# C7X256V_CORE0_C7X256V_CORE0_30240000h register map
Vendor: Texas Instruments
Peripheral module from a debugger description file (folder AM275x).
Registers are 32-bit, read-only, reset values left out (the file's numbers can be read two ways) unless marked. A register's access mark holds for its fields unless they carry their own. Offsets are as the file gives them; lines under a group give offsets from that group; [hi:lo] are bit positions; {n}, {i} and the like mark numbered series; 'fields as' and 'values as' point back to an identical list; <NAME> marks a mode.

## C7X256V_CORE0
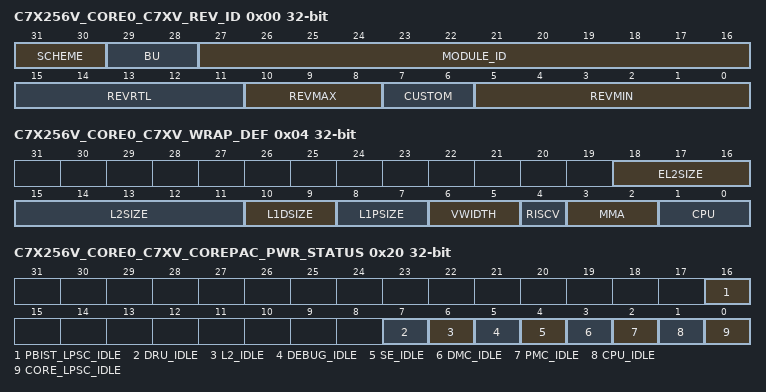
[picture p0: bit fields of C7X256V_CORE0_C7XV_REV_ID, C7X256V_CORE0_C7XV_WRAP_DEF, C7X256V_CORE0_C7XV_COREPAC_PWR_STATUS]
0x00 C7X256V_CORE0_C7XV_REV_ID — Revision parameters
  [31:30] SCHEME — Scheme Reset Source: mod_g_rst_n
  [29:28] BU — Scheme Reset Source: mod_g_rst_n
  [27:16] MODULE_ID — Module ID Reset Source: mod_g_rst_n
  [15:11] REVRTL — RTL version Reset Source: mod_g_rst_n
  [10:8] REVMAX — Major version Reset Source: mod_g_rst_n
  [7:6] CUSTOM — Custom version Reset Source: mod_g_rst_n
  [5:0] REVMIN — Minor version Reset Source: mod_g_rst_n
0x04 C7X256V_CORE0_C7XV_WRAP_DEF — Definition parameters
  [18:16] EL2SIZE — EL2 size Reset Source: mod_g_rst_n
  [15:11] L2SIZE — L2 size Reset Source: mod_g_rst_n
  [10:9] L1DSIZE — L1D size Reset Source: mod_g_rst_n
  [8:7] L1PSIZE — L1P size Reset Source: mod_g_rst_n
  [6:5] VWIDTH — Vector width size Reset Source: mod_g_rst_n
  [4] RISCV — RISCV ISA supported Reset Source: mod_g_rst_n
  [3:2] MMA — MMA type Reset Source: mod_g_rst_n
  [1:0] CPU — CPU type Reset Source: mod_g_rst_n
0x10 C7X256V_CORE0_C7XV_RESET_BOOT_VEC_L — C7xV wrap reset boot vector Register LSBs
  [31:0] RESET_BASE_VECTOR_LO — RVBARADDR0[31:0] Reset Source: mod_g_rst_n
0x14 C7X256V_CORE0_C7XV_RESET_BOOT_VEC_H — C7xV wrap reset boot vector Register MSBs
  [31:0] RESET_BASE_VECTOR_HI — RVBARADDR0[48:32] Reset Source: mod_g_rst_n
0x18 C7X256V_CORE0_C7XV_COREPAC_CFG — C7xV wrap corepac configuration register
  [0] CPU_SYS_RISCV_MODE — Enables CPU booting in RISC-V mode, default is C7xVISA mode Reset Source: mod_g_rst_n
0x1C C7X256V_CORE0_C7XV_COREPAC_PWR_CFG access not given — Configuration register
0x20 C7X256V_CORE0_C7XV_COREPAC_PWR_STATUS — C7xV wrap corepac power status register
  [16] PBIST_LPSC_IDLE — PBIST LPSC idle status Reset Source: mod_g_rst_n
  [7] DRU_IDLE — L2 idle status Reset Source: mod_g_rst_n
  [6] L2_IDLE — L2 idle status Reset Source: mod_g_rst_n
  [5] DEBUG_IDLE — Debug idle status Reset Source: mod_g_rst_n
  [4] SE_IDLE — SE idle status Reset Source: mod_g_rst_n
  [3] DMC_IDLE — DMC idle status Reset Source: mod_g_rst_n
  [2] PMC_IDLE — PMC idle status Reset Source: mod_g_rst_n
  [1] CPU_IDLE — CPU idle status Reset Source: mod_g_rst_n
  [0] CORE_LPSC_IDLE — Core LPSC idle status Reset Source: mod_g_rst_n
